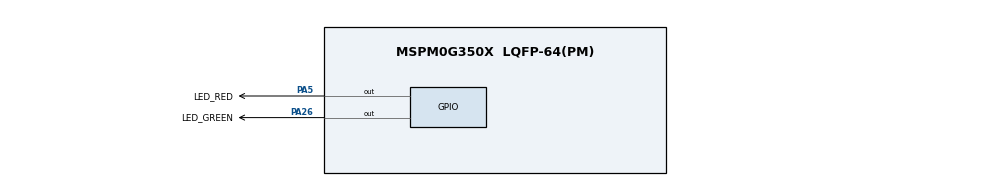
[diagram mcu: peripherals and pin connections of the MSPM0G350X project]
/**
 *
 * @cliArgs --device "MSPM0G350X" --part "Default" --package "LQFP-64(PM)" --product "mspm0_sdk@2.11.00.07"
 * @versions {"tool":"1.28.1+4785"}
 */

/**
 * Import the modules used in this configuration.
 */
const GPIO   = scripting.addModule("/ti/driverlib/GPIO", {}, false);
const GPIO1  = GPIO.addInstance();
const SYSCTL = scripting.addModule("/ti/driverlib/SYSCTL");

/**
 * Write custom configuration values to the imported modules.
 */
GPIO1.$name                          = "GPIO_LEDS";
GPIO1.port                           = "PORTA";
GPIO1.associatedPins.create(3);
GPIO1.associatedPins[0].$name        = "LED_GREEN";
GPIO1.associatedPins[0].assignedPin  = "26";
GPIO1.associatedPins[0].initialValue = "SET";
GPIO1.associatedPins[0].pin.$assign  = "PA26";
GPIO1.associatedPins[1].$name        = "LED_RED";
GPIO1.associatedPins[1].assignedPin  = "5";
GPIO1.associatedPins[1].initialValue = "SET";
GPIO1.associatedPins[1].pin.$assign  = "PA5";
GPIO1.associatedPins[2].$name        = "LED_BLUE";
GPIO1.associatedPins[2].initialValue = "SET";
GPIO1.associatedPins[2].assignedPin  = "6";

const Board = scripting.addModule("/ti/driverlib/Board", {}, false);

SYSCTL.forceDefaultClkConfig = true;
SYSCTL.clockTreeEn           = true;

/**
 * Pinmux solution for unlocked pins/peripherals. This ensures that minor changes to the automatic solver in a future
 * version of the tool will not impact the pinmux you originally saw.  These lines can be completely deleted in order to
 * re-solve from scratch.
 */
GPIO1.associatedPins[2].pin.$suggestSolution = "PA6";
Board.peripheral.$suggestSolution            = "DEBUGSS";
Board.peripheral.swclkPin.$suggestSolution   = "PA20";
Board.peripheral.swdioPin.$suggestSolution   = "PA19";
